# PIC32MK0128MCA048 device description
Architecture: MIPS; Family: PIC32MK; Series: PIC32MK
Registers are 32-bit, read-write, no defined reset value unless marked. A register's access mark holds for its fields unless they carry their own. Offsets are from the block's base; [hi:lo] are bit positions; 'fields as' and 'values as' point back to an identical list.

## OCMP
Instances: OCMP 0x1f824000 in periph_pb2_std
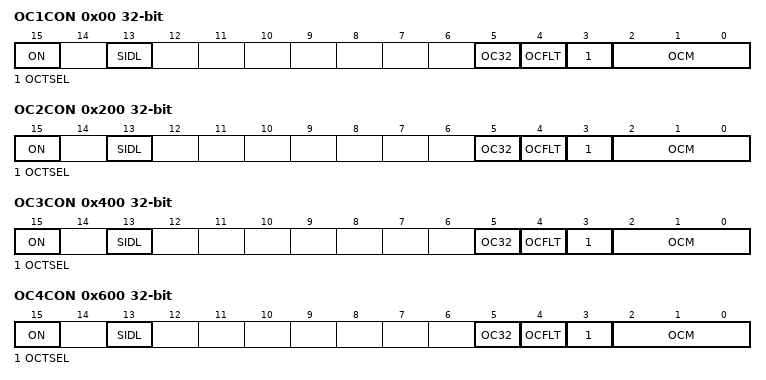
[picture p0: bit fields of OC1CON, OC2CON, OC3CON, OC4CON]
0x00 OC1CON — Output Compare 'x' Control Register
  [15] ON — Output Compare Peripheral On bit
    1=Output Compare peripheral is enabled; 0=Output Compare peripheral is disabled
  [13] SIDL — Stop in Idle Mode bit
    1=Discontinue operation when CPU enters Idle mode; 0=Continue operation in Idle mode
  [5] OC32 — 32-bit Compare Mode bit
    1=OCxR(31-0) and/or OCxRS(31-0) are used for comparisions to the 32-bit timer source; 0=OCxR(15-0) and OCxRS(15-0) are used for comparisons to the 16-bit timer source
  [4] OCFLT — PWM Fault Condition Status bit
    1=PWM Fault condition has occurred (cleared in HW only); 0=No PWM Fault condition has occurred
  [3] OCTSEL — Output Compare Timer Select bit
    1=Timer3 is the clock source for this Output Compare module; 0=Timer2 is the clock source for this Output Compare module
  [2:0] OCM — Output Compare Mode Select bits
    7=PWM mode on OCx; Fault pin enabled; 6=PWM mode on OCx; Fault pin disabled; 5=Initialize OCx pin low; generate continious output pulses on OCx pin; 4=Initialize OCx pin low: generate single output pulse on OCx pin; 3=Compare event toggles OCx pin; 2=Initialize OCx pin high; compare event forces OCx pin low; 1=Initialize OCx pin low; compare event forces OCx pin high; 0=Output compare peripheral is disabled but continues to draw current
0x10 OC1R
0x20 OC1RS
0x200 OC2CON — Output Compare 'x' Control Register
  fields as OC1CON
0x210 OC2R
0x220 OC2RS
0x400 OC3CON — Output Compare 'x' Control Register
  fields as OC1CON
0x410 OC3R
0x420 OC3RS
0x600 OC4CON — Output Compare 'x' Control Register
  fields as OC1CON
0x610 OC4R
0x620 OC4RS

## PCACHE
Instances: PCACHE 0x1f800800 in periph_pb1_std
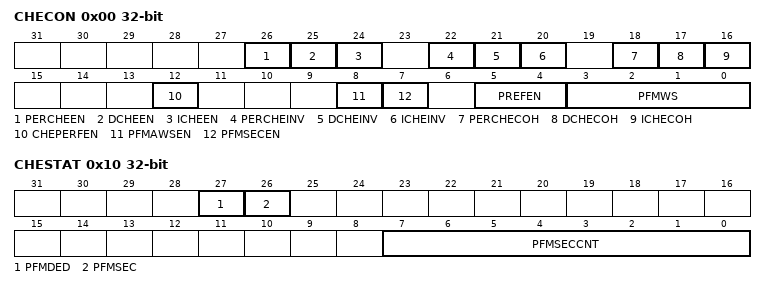
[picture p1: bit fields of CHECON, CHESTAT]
0x00 CHECON
  [26] PERCHEEN, [25] DCHEEN, [24] ICHEEN, [22] PERCHEINV, [21] DCHEINV, [20] ICHEINV, [18] PERCHECOH, [17] DCHECOH, [16] ICHECOH, [12] CHEPERFEN, [8] PFMAWSEN, [7] PFMSECEN, [5:4] PREFEN, [3:0] PFMWS
0x10 CHESTAT
  [27] PFMDED, [26] PFMSEC, [7:0] PFMSECCNT
0x20 CHEHIT ro
0x30 CHEMIS ro

## RCON
Instances: RCON 0x1f801240 in periph_pb1_std
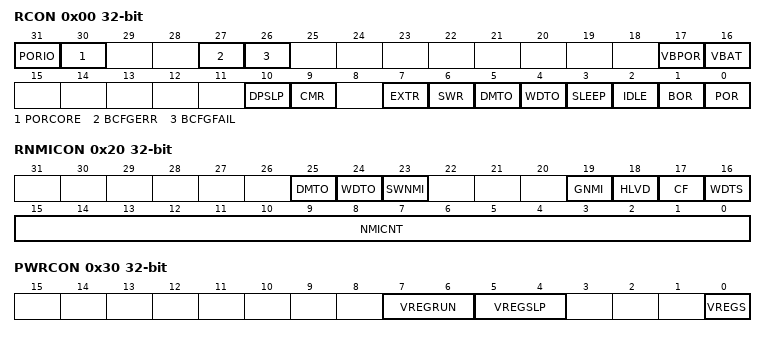
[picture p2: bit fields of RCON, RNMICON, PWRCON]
0x00 RCON — Reset Control Register
  [31] PORIO
  [30] PORCORE
  [27] BCFGERR — Primary Configuration Registers Error Flag bit
    0=An error occurred during a read of the primary configuration registers; 0=No error occurred during a read of the primary configuration registers
  [26] BCFGFAIL — Primary/Secondary Configuration Registers Error Flag bit
    0=An error occurred during a read of the primary and alternate configuration registers; 0=No error occurred during a read of the primary and alternate configuration registers
  [17] VBPOR — VBPOR Mode Flag bit
  [16] VBAT — VBAT Mode Flag bit
  [10] DPSLP — Deep Sleep Mode Flag bit
  [9] CMR — Configuration Mismatch Reset Flag bit
    1=A Configuration Mismatch Reset has occurred; 0=A Configuration Mismatch Reset has not occurred
  [7] EXTR — External Reset Pin Flag bit
    1=Master Clear (pin) Reset has occurred; 0=Master Clear (pin) Reset has not occurred
  [6] SWR — Software Reset Flag bit
    1=Software Reset was executed; 0=Software Reset was not executed
  [5] DMTO
  [4] WDTO — Watchdog Timer Time-out Flag bit
    1=WDT Time-out has occurred; 0=WDT Time-out has not occurred
  [3] SLEEP — Wake From Sleep Flag bit
    1=Device was in Sleep mode; 0=Device was not in Sleep mode
  [2] IDLE — Wake From Idle Flag bit
    1=Device was in Idle mode; 0=Device was not in Idle mode
  [1] BOR — Brown-out Reset Flag bit
    1=Brown-out Reset has occurred; 0=Brown-out Reset has not occurred
  [0] POR — Power-on Reset Flag bit
    1=Power-on Reset has occurred; 0=Power-on Reset has not occurred
0x10 RSWRST wo
  [0] SWRST
0x20 RNMICON — Non-Maskable Interrupt (NMI) Control Register
  [25] DMTO
  [24] WDTO — Run Time Watchdog Timer Time-Out Flag bit
    1=WDT time-out has occurred and caused a NMI; 0=WDT time-out has not occurred
  [23] SWNMI — Software NMI Trigger
    1=An NMI will be generated; 0=An NMI will not be generated
  [19] GNMI — General NMI bit
    1=A general NMI event has been detected or a user-initiated NMI event has occurred; 0=A general NMI event has not been detected
  [18] HLVD
  [17] CF — Clock Fail Detect bit
    1=FSCM has detected clock failure and caused an NMI; 0=FSCM has not detected clock failure
  [16] WDTS — Watchdog Timer Time-out in Sleep Mode Flag bit
    1=WDT time-out has occurred during Sleep mode and caused a wake-up from sleep; 0=WDT time-out has not occurred during Sleep mode
  [15:0] NMICNT — NMI Reset Counter Value bits
    0xffff=65535 SYSCLK cycles before a device Reset occurs; 2=2 SYSCLK cycle before a device Reset occurs; 1=1 SYSCLK cycle before a device Reset occurs; 0=No delay between NMI assertion and device Reset event
0x30 PWRCON
  [7:6] VREGRUN
  [5:4] VREGSLP
  [0] VREGS — Voltage Regulator Stand-by Enable bit
    1=Voltage regulator will remain active during Sleep; 0=Voltage regulator will go to Stand-by mode during Sleep
